# max32620 register map
Vendor: Maxim Integrated; Series: ARMCM4; File version: 1.1
CPU: CM4 r1p0, little endian, no MPU, FPU, 3 interrupt priority bits
Registers are 32-bit, read-write, reset 0x0 unless marked. A register's access mark holds for its fields unless they carry their own. Offsets are from the block's base; [hi:lo] are bit positions.

## PWRSEQ — Power Sequencer
Base 0x40000A30
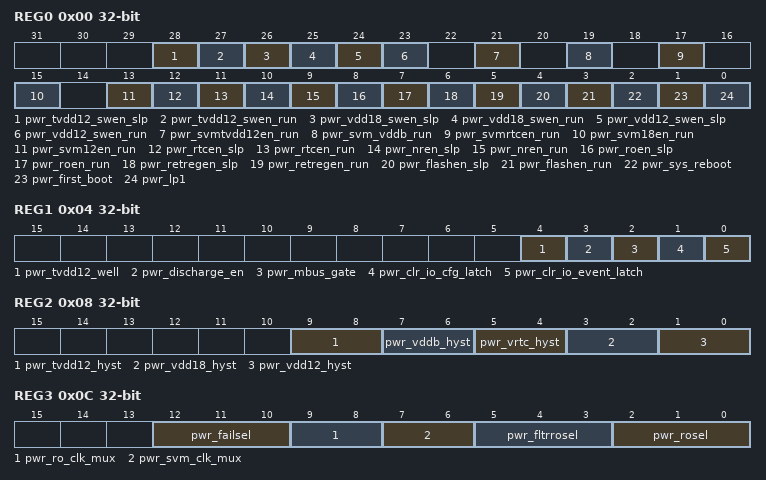
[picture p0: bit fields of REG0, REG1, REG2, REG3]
0x00 REG0 — Power Sequencer Control Register 0
  [28] pwr_tvdd12_swen_slp — Enable TVDD12 switching during Sleep Mode
  [27] pwr_tvdd12_swen_run — Enable TVDD12 switching during Run Mode
  [26] pwr_vdd18_swen_slp — Enable VDD18 switching during Sleep Mode
  [25] pwr_vdd18_swen_run — Enable VDD18 switching during Run Mode
  [24] pwr_vdd12_swen_slp — Enable VDD12 switching during Sleep Mode
  [23] pwr_vdd12_swen_run — Enable VDD12 switching during Run Mode
  [21] pwr_svmtvdd12en_run — Enable TVDD12 SVM operation during Run Mode
  [19] pwr_svm_vddb_run — Enable VDDB SVM operation during Run Mode
  [17] pwr_svmrtcen_run — Enable VRTC SVM operation during Run Mode
  [15] pwr_svm18en_run — Enable VDD18_SW SVM operation during Run Mode
  [13] pwr_svm12en_run — Enable VDD12_SW SVM operation during Run Mode
  [12] pwr_rtcen_slp — Enable Real Time Clock Operation during Sleep Mode
  [11] pwr_rtcen_run — Enable Real Time Clock Operation during Run Mode
  [10] pwr_nren_slp — Enable Nano Oscillator in Sleep Mode
  [9] pwr_nren_run — Enable Nano Oscillator in Run Mode
  [8] pwr_roen_slp — Enable 96MHz System Relaxation Oscillator in Sleep Mode
  [7] pwr_roen_run — Enable 96MHz System Relaxation Oscillator in Run Mode
  [6] pwr_retregen_slp — Enable Retention Regulator Operation during Sleep Mode
  [5] pwr_retregen_run — Enable Retention Regulator Operation during Run Mode
  [4] pwr_flashen_slp — Enable Flash Operation during Sleep Mode
  [3] pwr_flashen_run — Enable Flash Operation during Run Mode
  [2] pwr_sys_reboot wo — Firmware System Reboot Request
  [1] pwr_first_boot — Wake on First Boot
  [0] pwr_lp1 — Shutdown Power Mode Select
0x04 REG1 — Power Sequencer Control Register 1
  [4] pwr_tvdd12_well — TVDD12 Well Switch
  [3] pwr_discharge_en — Enable Flash Discharge During Powerfail Event
  [2] pwr_mbus_gate — Freeze GPIO MBus State
  [1] pwr_clr_io_cfg_latch — Clear all GPIO Configuration Latches
  [0] pwr_clr_io_event_latch — Clear all GPIO Event Seen Latches
0x08 REG2 — Power Sequencer Control Register 2
  [9:8] pwr_tvdd12_hyst — TVDD12 Comparator Hysteresis Setting
  [7:6] pwr_vddb_hyst — VDDB Comparator Hysteresis Setting
  [5:4] pwr_vrtc_hyst — VRTC Comparator Hysteresis Setting
  [3:2] pwr_vdd18_hyst — VDD18_SW Comparator Hysteresis Setting
  [1:0] pwr_vdd12_hyst — VDD12_SW Comparator Hysteresis Setting
0x0C REG3 — Power Sequencer Control Register 3
  [12:10] pwr_failsel — Timeout before rebooting during PowerFail/BootFail events.
  [9:8] pwr_ro_clk_mux — Relaxation Clock Mux
  [7:6] pwr_svm_clk_mux — SVM Clock Mux
  [5:3] pwr_fltrrosel — Window of time power must be valid before entering Run mode.
  [2:0] pwr_rosel — Relaxation Oscillator Stable Timeout
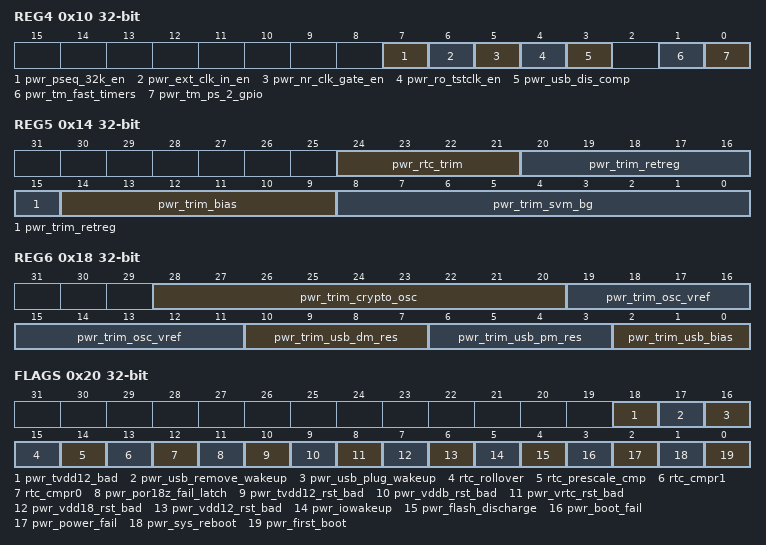
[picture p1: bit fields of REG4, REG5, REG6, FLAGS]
0x10 REG4 — Power Sequencer Control Register 4 (Internal Test Only)
  [7] pwr_pseq_32k_en — Internal Use Only
  [6] pwr_ext_clk_in_en — Internal Use Only
  [5] pwr_nr_clk_gate_en — Internal Use Only
  [4] pwr_ro_tstclk_en — Internal Use Only
  [3] pwr_usb_dis_comp — Internal Use Only
  [1] pwr_tm_fast_timers — Internal Use Only
  [0] pwr_tm_ps_2_gpio — Internal Use Only
0x14 REG5 — Power Sequencer Control Register 5 (Trim 0)
  [24:21] pwr_rtc_trim — Real Time Clock trim setting
  [20:15] pwr_trim_retreg — Retention Regulator trim setting
  [14:9] pwr_trim_bias — Power Manager Bias Current trim setting
  [8:0] pwr_trim_svm_bg — Power Manager Bandgap trim setting
0x18 REG6 — Power Sequencer Control Register 6 (Trim 1)
  [28:20] pwr_trim_crypto_osc — Crypto Oscillator trim setting
  [19:11] pwr_trim_osc_vref — Relaxation Oscillator trim setting
  [10:7] pwr_trim_usb_dm_res — USB Data Minus Slew Rate trim setting
  [6:3] pwr_trim_usb_pm_res — USB Data Plus Slew Rate trim setting
  [2:0] pwr_trim_usb_bias — USB Bias Current trim setting
0x1C REG7 — Power Sequencer Control Register 7
  [0] pwr_flash_pd_lookahead ro — Flash Powerdown Lookahead Flag
0x20 FLAGS — Power Sequencer Flags
  [18] pwr_tvdd12_bad write-1-clears — Retention Regulator POR Tripped event detected flag
  [17] pwr_usb_remove_wakeup write-1-clears — USB Power Remove Wakeup event detected flag
  [16] pwr_usb_plug_wakeup write-1-clears — USB Power Connect Wakeup event detected flag
  [15] rtc_rollover ro — RTC Rollover event detected flag
  [14] rtc_prescale_cmp ro — RTC Prescale Comparator Match event detected flag
  [13] rtc_cmpr1 ro — RTC Comparator 1 Match event detected flag
  [12] rtc_cmpr0 ro — RTC Comparator 0 Match event detected flag
  [11] pwr_por18z_fail_latch write-1-clears — POR18 and POR18_bg have been tripped
  [10] pwr_tvdd12_rst_bad write-1-clears — TVDD12 Comparator Tripped event detected flag
  [9] pwr_vddb_rst_bad write-1-clears — VDDB Comparator Tripped event detected flag
  [8] pwr_vrtc_rst_bad write-1-clears — VRTC Comparator Tripped event detected flag
  [7] pwr_vdd18_rst_bad write-1-clears — VDD18_SW Comparator Tripped event detected flag
  [6] pwr_vdd12_rst_bad write-1-clears — VDD12_SW Comparator Tripped event detected flag
  [5] pwr_iowakeup write-1-clears — GPIO Wakeup event detected flag
  [4] pwr_flash_discharge write-1-clears — Flash Discharged During Powerfail event detected flag
  [3] pwr_boot_fail write-1-clears — Boot Fail event detected flag
  [2] pwr_power_fail write-1-clears — Power Fail event detected flag
  [1] pwr_sys_reboot ro — Firmware Reset event detected flag
  [0] pwr_first_boot ro — Initial Boot event detected flag
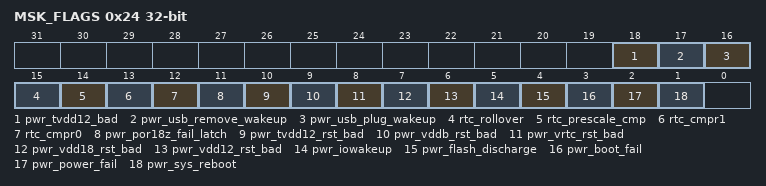
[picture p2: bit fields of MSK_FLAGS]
0x24 MSK_FLAGS — Power Sequencer Flags Mask Register
  [18] pwr_tvdd12_bad — Mask for TVDD12 power fail event
  [17] pwr_usb_remove_wakeup — Mask for USB plug disconnect event
  [16] pwr_usb_plug_wakeup — Mask for USB plug connect event
  [15] rtc_rollover — Mask for RTC rollover event
  [14] rtc_prescale_cmp — Mask for RTC prescale compare event
  [13] rtc_cmpr1 — Mask for RTC compare 1 event
  [12] rtc_cmpr0 — Mask for RTC compare 0 event
  [11] pwr_por18z_fail_latch — Mask for POR18 powerfail event
  [10] pwr_tvdd12_rst_bad — Mask for TVDD12 rst event
  [9] pwr_vddb_rst_bad — Mask for VDDB rst event
  [8] pwr_vrtc_rst_bad — Mask for VRTC rst event
  [7] pwr_vdd18_rst_bad — Mask for VDD18 rst event
  [6] pwr_vdd12_rst_bad — Mask for VDD12 rst event
  [5] pwr_iowakeup — Mask for GPIO wakeup event detect
  [4] pwr_flash_discharge — Mask for flash discharge event
  [3] pwr_boot_fail — Mask for previous boot fail detect
  [2] pwr_power_fail — Mask for previous power fail detect
  [1] pwr_sys_reboot — Mask for system reboot detect
